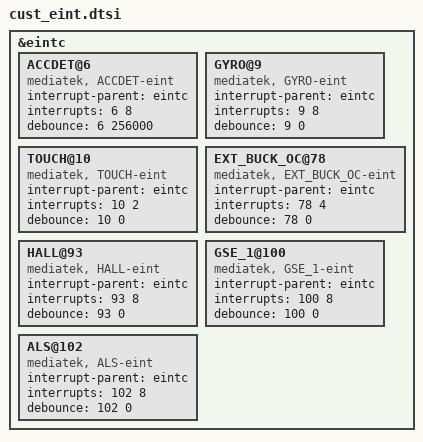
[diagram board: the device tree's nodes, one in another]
/*
 * Generated by MTK SP DrvGen Version 03.13.6 for MT6735M. Copyright MediaTek Inc. (C) 2013.
 * Thu May 12 14:21:30 2016
 * Do Not Modify the File.
 */

/*************************
 * EINT DTSI File
*************************/

&eintc {
	ACCDET@6 {
		compatible = "mediatek, ACCDET-eint";
		interrupt-parent = <&eintc>;
		interrupts = <6 8>;
		debounce = <6 256000>;
	};

	GYRO@9 {
		compatible = "mediatek, GYRO-eint";
		interrupt-parent = <&eintc>;
		interrupts = <9 8>;
		debounce = <9 0>;
	};

	TOUCH@10 {
		compatible = "mediatek, TOUCH-eint";
		interrupt-parent = <&eintc>;
		interrupts = <10 2>;
		debounce = <10 0>;
	};

	EXT_BUCK_OC@78 {
		compatible = "mediatek, EXT_BUCK_OC-eint";
		interrupt-parent = <&eintc>;
		interrupts = <78 4>;
		debounce = <78 0>;
	};

	HALL@93 {
		compatible = "mediatek, HALL-eint";
		interrupt-parent = <&eintc>;
		interrupts = <93 8>;
		debounce = <93 0>;
	};

	GSE_1@100 {
		compatible = "mediatek, GSE_1-eint";
		interrupt-parent = <&eintc>;
		interrupts = <100 8>;
		debounce = <100 0>;
	};

	ALS@102 {
		compatible = "mediatek, ALS-eint";
		interrupt-parent = <&eintc>;
		interrupts = <102 8>;
		debounce = <102 0>;
	};

};
